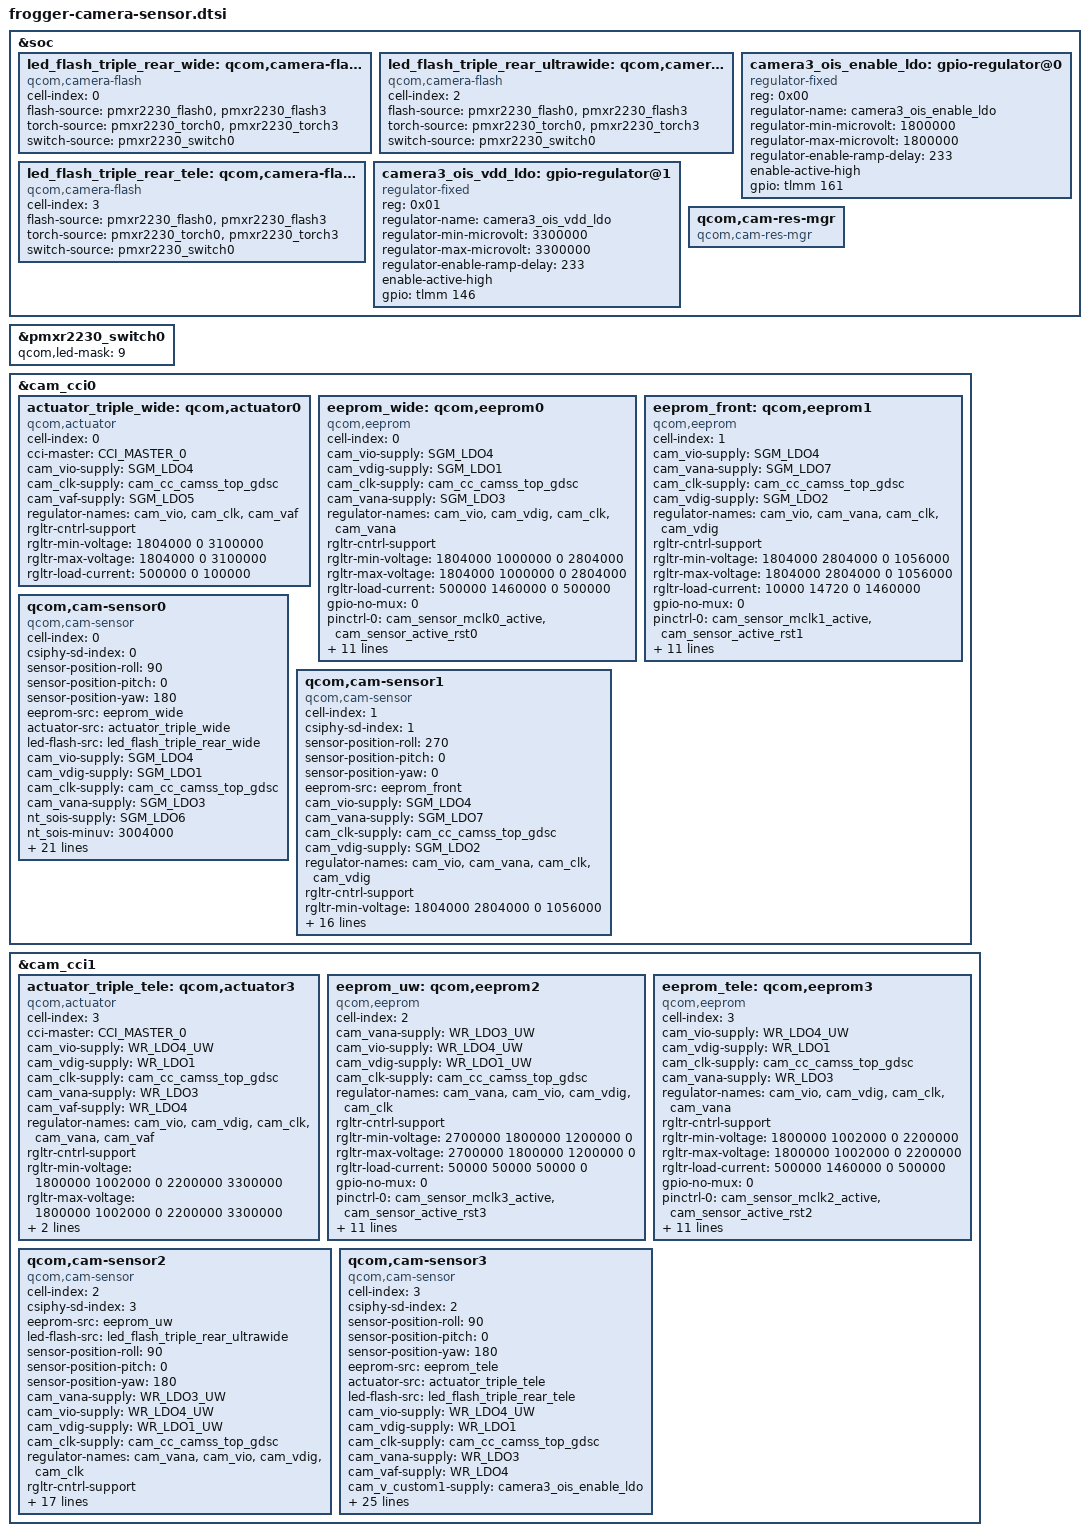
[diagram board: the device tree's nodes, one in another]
/*
 * Frogger camera sensors.
 *
 * Ported from the OEM camera-devicetree module
 * (vendor/qcom/proprietary/camera-devicetree/frogger-camera-sensor.dtsi), which
 * this tree does not carry. Kept as close to the original as possible so it can
 * be re-diffed against a newer OEM drop; only the CRLF line endings and a few
 * stray space indents were normalised.
 *
 * Four sensors:
 *   cam-sensor0  cci0  csiphy0  wide       S5KGN9,  eeprom + actuator + flash
 *   cam-sensor1  cci0  csiphy1  front      S5KKD1,  eeprom
 *   cam-sensor2  cci1  csiphy3  ultrawide  IMX355,  eeprom + flash
 *   cam-sensor3  cci1  csiphy2  tele       S5KJN5,  eeprom + actuator + OIS
 *
 * The tele is a Phone (4a) Pro part and is not populated on a plain Frogger.
 * Stock ships this same node set for both board-ids and the sensor simply fails
 * to probe when absent, so it is kept rather than stripped.
 *
 * The SGM_LDO* / WR_LDO* supplies come from frogger-camera-supply.dtsi, which
 * frogger-common.dtsi already includes into this overlay.
 *
 * cam_cci0/1, the cam_sensor_* pinctrl, camcc and the pmxr2230 flash labels are
 * NOT defined here and must not be. They come from the merged base, which is
 * volcano.dtb plus its platform dtbos, and resolve through __fixups__ at overlay
 * application -- see the comment in frogger-base-overlay.dts.
 *
 * camcc-volcano.h is needed for the CAM_CC_MCLK*_CLK clock ids. It arrives via
 * volcano.dtsi in a normal build, but this overlay includes volcano-qrd.dtsi,
 * which does not pull volcano.dtsi in, so it has to be included directly. QCOM's
 * own standalone camera .dts files do the same thing for the same reason.
 */

#include <dt-bindings/clock/qcom,camcc-volcano.h>
#include <dt-bindings/msm-camera.h>

&soc {
	led_flash_triple_rear_wide: qcom,camera-flash0 {
		cell-index = <0>;
		compatible = "qcom,camera-flash";
		flash-source = <&pmxr2230_flash0 &pmxr2230_flash3>;
		torch-source = <&pmxr2230_torch0 &pmxr2230_torch3>;
		switch-source = <&pmxr2230_switch0>;
		status = "ok";
	};

	led_flash_triple_rear_ultrawide: qcom,camera-flash1 {
		cell-index = <2>;
		compatible = "qcom,camera-flash";
		flash-source = <&pmxr2230_flash0 &pmxr2230_flash3>;
		torch-source = <&pmxr2230_torch0 &pmxr2230_torch3>;
		switch-source = <&pmxr2230_switch0>;
		status = "ok";
	};

	led_flash_triple_rear_tele: qcom,camera-flash2 {
		cell-index = <3>;
		compatible = "qcom,camera-flash";
		flash-source = <&pmxr2230_flash0 &pmxr2230_flash3>;
		torch-source = <&pmxr2230_torch0 &pmxr2230_torch3>;
		switch-source = <&pmxr2230_switch0>;
		status = "ok";
	};


	camera3_ois_enable_ldo: gpio-regulator@0 {
		compatible = "regulator-fixed";
		reg = <0x00>;
		regulator-name = "camera3_ois_enable_ldo";
		regulator-min-microvolt = <1800000>;
		regulator-max-microvolt = <1800000>;
		regulator-enable-ramp-delay = <233>;
		enable-active-high;
		gpio = <&tlmm 161 0>;
	};

	camera3_ois_vdd_ldo: gpio-regulator@1 {
		compatible = "regulator-fixed";
		reg = <0x01>;
		regulator-name = "camera3_ois_vdd_ldo";
		regulator-min-microvolt = <3300000>;
		regulator-max-microvolt = <3300000>;
		regulator-enable-ramp-delay = <233>;
		enable-active-high;
		gpio = <&tlmm 146 0>;
	};

	qcom,cam-res-mgr {
		compatible = "qcom,cam-res-mgr";
		status = "ok";
	};
};

&pmxr2230_switch0 {
	qcom,led-mask = <9>; // Channels 1 & 4
	// qcom,symmetry-en;
};

&cam_cci0 {

	actuator_triple_wide: qcom,actuator0 {
		cell-index = <0>;
		compatible = "qcom,actuator";
		cci-master = <CCI_MASTER_0>;
		cam_vio-supply = <&SGM_LDO4>;
		cam_clk-supply = <&cam_cc_camss_top_gdsc>;
		cam_vaf-supply = <&SGM_LDO5>;
		regulator-names = "cam_vio", "cam_clk", "cam_vaf";
		rgltr-cntrl-support;
		rgltr-min-voltage = <1804000 0 3100000>;
		rgltr-max-voltage = <1804000 0 3100000>;
		rgltr-load-current = <500000 0 100000>;
		status = "ok";
	};

	eeprom_wide: qcom,eeprom0 {
		cell-index = <0>;
		compatible = "qcom,eeprom";
		cam_vio-supply = <&SGM_LDO4>;
		cam_vdig-supply = <&SGM_LDO1>;
		cam_clk-supply = <&cam_cc_camss_top_gdsc>;
		cam_vana-supply = <&SGM_LDO3>;
		regulator-names = "cam_vio", "cam_vdig", "cam_clk",
			"cam_vana";
		rgltr-cntrl-support;
		rgltr-min-voltage = <1804000 1000000 0 2804000>;
		rgltr-max-voltage = <1804000 1000000 0 2804000>;
		rgltr-load-current = <500000 1460000 0 500000>;
		gpio-no-mux = <0>;
		pinctrl-names = "cam_default", "cam_suspend";
		pinctrl-0 = <&cam_sensor_mclk0_active
				 &cam_sensor_active_rst0>;
		pinctrl-1 = <&cam_sensor_mclk0_suspend
				 &cam_sensor_suspend_rst0>;
		gpios = <&tlmm 83 0>,
			<&tlmm 40 0>;
		gpio-reset = <1>;
		gpio-req-tbl-num = <0 1>;
		gpio-req-tbl-flags = <1 0>;
		gpio-req-tbl-label = "CAMIF_MCLK0",
					"CAM_RESET0";
		cci-master = <CCI_MASTER_0>;
		clocks = <&camcc CAM_CC_MCLK0_CLK>;
		clock-names = "cam_clk";
		clock-cntl-level = "nominal";
		clock-rates = <19200000>;
		status = "ok";
	};

	eeprom_front: qcom,eeprom1 {
		cell-index = <1>;
		compatible = "qcom,eeprom";
		cam_vio-supply = <&SGM_LDO4>;
		cam_vana-supply = <&SGM_LDO7>;
		cam_clk-supply = <&cam_cc_camss_top_gdsc>;
		cam_vdig-supply = <&SGM_LDO2>;
		regulator-names = "cam_vio", "cam_vana", "cam_clk", "cam_vdig";
		rgltr-cntrl-support;
		rgltr-min-voltage = <1804000 2804000 0 1056000>;
		rgltr-max-voltage = <1804000 2804000 0 1056000>;
		rgltr-load-current = <10000 14720 0 1460000>;
		gpio-no-mux = <0>;
		pinctrl-names = "cam_default", "cam_suspend";
		pinctrl-0 = <&cam_sensor_mclk1_active
				 &cam_sensor_active_rst1>;
		pinctrl-1 = <&cam_sensor_mclk1_suspend
				 &cam_sensor_suspend_rst1>;
		gpios = <&tlmm 84 0>,
			<&tlmm 41 0>;
		gpio-reset = <1>;
		gpio-req-tbl-num = <0 1>;
		gpio-req-tbl-flags = <1 0>;
		gpio-req-tbl-label = "CAMIF_MCLK1",
					"CAM_RESET1";
		cci-master = <CCI_MASTER_1>;
		clocks = <&camcc CAM_CC_MCLK1_CLK>;
		clock-names = "cam_clk";
		clock-cntl-level = "nominal";
		clock-rates = <19200000>;
		status = "ok";
	};

	/* Sensor (Wide GNJ) */
	qcom,cam-sensor0 {
		cell-index = <0>;
		compatible = "qcom,cam-sensor";
		csiphy-sd-index = <0>;
		sensor-position-roll = <90>;
		sensor-position-pitch = <0>;
		sensor-position-yaw = <180>;
		eeprom-src = <&eeprom_wide>;
		actuator-src = <&actuator_triple_wide>;
		led-flash-src = <&led_flash_triple_rear_wide>;
		cam_vio-supply = <&SGM_LDO4>;
		cam_vdig-supply = <&SGM_LDO1>;
		cam_clk-supply = <&cam_cc_camss_top_gdsc>;
		cam_vana-supply = <&SGM_LDO3>;
		// cam_v_custom1-supply = <&SGM_LDO6>;
		nt_sois-supply = <&SGM_LDO6>;
		nt_sois-minuv = <3004000>;
		nt_sois-maxuv = <3004000>;
		regulator-names = "cam_vio", "cam_vdig", "cam_clk",
			"cam_vana";
		rgltr-cntrl-support;
		rgltr-min-voltage = <1804000 1048000 0 2804000>;
		rgltr-max-voltage = <1804000 1048000 0 2804000>;
		rgltr-load-current = <500000 1460000 0 500000>;
		gpio-no-mux = <0>;
		pinctrl-names = "cam_default", "cam_suspend";
		pinctrl-0 = <&cam_sensor_mclk0_active
				 &cam_sensor_active_rst0>;
		pinctrl-1 = <&cam_sensor_mclk0_suspend
				 &cam_sensor_suspend_rst0>;
		gpios = <&tlmm 83 0>,
			<&tlmm 40 0>;
		gpio-reset = <1>;
		gpio-req-tbl-num = <0 1>;
		gpio-req-tbl-flags = <1 0>;
		gpio-req-tbl-label = "CAMIF_MCLK0",
					"CAM_RESET0";
		cci-master = <CCI_MASTER_0>;
		clocks = <&camcc CAM_CC_MCLK0_CLK>;
		clock-names = "cam_clk";
		clock-cntl-level = "nominal";
		clock-rates = <19200000>;
		status = "ok";
	};

	/*sensor front 32M*/
	qcom,cam-sensor1 {
		cell-index = <1>;
		compatible = "qcom,cam-sensor";
		csiphy-sd-index = <1>;
		sensor-position-roll = <270>;
		sensor-position-pitch = <0>;
		sensor-position-yaw = <0>;
		eeprom-src = <&eeprom_front>;
		cam_vio-supply = <&SGM_LDO4>;
		cam_vana-supply = <&SGM_LDO7>;
		cam_clk-supply = <&cam_cc_camss_top_gdsc>;
		cam_vdig-supply = <&SGM_LDO2>;
		regulator-names = "cam_vio", "cam_vana", "cam_clk", "cam_vdig";
		rgltr-cntrl-support;
		rgltr-min-voltage = <1804000 2804000 0 1056000>;
		rgltr-max-voltage = <1804000 2804000 0 1056000>;
		rgltr-load-current = <10000 14720 0 1460000>;
		gpio-no-mux = <0>;
		pinctrl-names = "cam_default", "cam_suspend";
		pinctrl-0 = <&cam_sensor_mclk1_active
				 &cam_sensor_active_rst1>;
		pinctrl-1 = <&cam_sensor_mclk1_suspend
				 &cam_sensor_suspend_rst1>;
		gpios = <&tlmm 84 0>,
			<&tlmm 41 0>;
		gpio-reset = <1>;
		gpio-req-tbl-num = <0 1>;
		gpio-req-tbl-flags = <1 0>;
		gpio-req-tbl-label = "CAMIF_MCLK1",
					"CAM_RESET1";
		cci-master = <CCI_MASTER_1>;
		clocks = <&camcc CAM_CC_MCLK1_CLK>;
		clock-names = "cam_clk";
		clock-cntl-level = "nominal";
		clock-rates = <19200000>;
		status = "ok";
	};
};

&cam_cci1 {
		actuator_triple_tele: qcom,actuator3 {
		cell-index = <3>;
		compatible = "qcom,actuator";
		cci-master = <CCI_MASTER_0>;
		cam_vio-supply = <&WR_LDO4_UW>;
		cam_vdig-supply = <&WR_LDO1>;
		cam_clk-supply = <&cam_cc_camss_top_gdsc>;
		cam_vana-supply = <&WR_LDO3>;
		cam_vaf-supply = <&WR_LDO4>;
		regulator-names = "cam_vio", "cam_vdig", "cam_clk", "cam_vana", "cam_vaf";
		rgltr-cntrl-support;
		rgltr-min-voltage = <1800000 1002000 0 2200000 3300000>;
		rgltr-max-voltage = <1800000 1002000 0 2200000 3300000>;
		rgltr-load-current = <500000 1460000 0 500000 100000>;
		status = "ok";
	};

	eeprom_uw: qcom,eeprom2 {
		cell-index = <2>;
		compatible = "qcom,eeprom";
		cam_vana-supply = <&WR_LDO3_UW>;
		cam_vio-supply = <&WR_LDO4_UW>;
		cam_vdig-supply = <&WR_LDO1_UW>;
		cam_clk-supply = <&cam_cc_camss_top_gdsc>;
		regulator-names = "cam_vana", "cam_vio", "cam_vdig",
			 "cam_clk";
		rgltr-cntrl-support;
		rgltr-min-voltage = <2700000 1800000 1200000 0>;
		rgltr-max-voltage = <2700000 1800000 1200000 0>;
		rgltr-load-current = <50000 50000 50000 0>;
		gpio-no-mux = <0>;
		pinctrl-names = "cam_default", "cam_suspend";
		pinctrl-0 = <&cam_sensor_mclk3_active
			&cam_sensor_active_rst3>;
		pinctrl-1 = <&cam_sensor_mclk3_suspend
			&cam_sensor_suspend_rst3>;
		gpios = <&tlmm 86 0>, <&tlmm 43 0>;
		gpio-reset = <1>;
		gpio-req-tbl-num = <0 1>;
		gpio-req-tbl-flags = <1 0>;
		gpio-req-tbl-label = "CAMIF_MCLK3", "CAM_RESET3";
		cci-master = <CCI_MASTER_1>;
		clocks = <&camcc CAM_CC_MCLK3_CLK>;
		clock-names = "cam_clk";
		clock-cntl-level = "nominal";
		clock-rates = <19200000>;
		status = "ok";
	};

	eeprom_tele: qcom,eeprom3{
		cell-index = <3>;
		compatible = "qcom,eeprom";
		cam_vio-supply = <&WR_LDO4_UW>;
		cam_vdig-supply = <&WR_LDO1>;
		cam_clk-supply = <&cam_cc_camss_top_gdsc>;
		cam_vana-supply = <&WR_LDO3>;
		regulator-names = "cam_vio", "cam_vdig", "cam_clk", "cam_vana";
		rgltr-cntrl-support;
		rgltr-min-voltage = <1800000 1002000 0 2200000>;
		rgltr-max-voltage = <1800000 1002000 0 2200000>;
		rgltr-load-current = <500000 1460000 0 500000>;
		gpio-no-mux = <0>;
		pinctrl-names = "cam_default", "cam_suspend";
		pinctrl-0 = <&cam_sensor_mclk2_active
				 &cam_sensor_active_rst2>;
		pinctrl-1 = <&cam_sensor_mclk2_suspend
				 &cam_sensor_suspend_rst2>;
		gpios = <&tlmm 85 0>,
			<&tlmm 42 0>;
		gpio-reset = <1>;
		gpio-req-tbl-num = <0 1>;
		gpio-req-tbl-flags = <1 0>;
		gpio-req-tbl-label = "CAMIF_MCLK2",
					"CAM_RESET2";
		cci-master = <CCI_MASTER_0>;
		clocks = <&camcc CAM_CC_MCLK2_CLK>;
		clock-names = "cam_clk";
		clock-cntl-level = "nominal";
		clock-rates = <19200000>;
		status = "ok";
	};

	/* Sensor (Ultra imx355) */
	qcom,cam-sensor2 {
		cell-index = <2>;
		compatible = "qcom,cam-sensor";
		csiphy-sd-index = <3>;
		eeprom-src = <&eeprom_uw>;
		led-flash-src = <&led_flash_triple_rear_ultrawide>;
		sensor-position-roll = <90>;
		sensor-position-pitch = <0>;
		sensor-position-yaw = <180>;
		cam_vana-supply = <&WR_LDO3_UW>;
		cam_vio-supply = <&WR_LDO4_UW>;
		cam_vdig-supply = <&WR_LDO1_UW>;
		cam_clk-supply = <&cam_cc_camss_top_gdsc>;
		regulator-names = "cam_vana", "cam_vio", "cam_vdig",
			 "cam_clk";
		rgltr-cntrl-support;
		rgltr-min-voltage = <2700000 1800000 1200000 0>;
		rgltr-max-voltage = <2700000 1800000 1200000 0>;
		rgltr-load-current = <50000 50000 50000 0>;
		gpio-no-mux = <0>;
		pinctrl-names = "cam_default", "cam_suspend";
		pinctrl-0 = <&cam_sensor_mclk3_active
			&cam_sensor_active_rst3>;
		pinctrl-1 = <&cam_sensor_mclk3_suspend
			&cam_sensor_suspend_rst3>;
		gpios = <&tlmm 86 0>, <&tlmm 43 0>;
		gpio-reset = <1>;
		gpio-req-tbl-num = <0 1>;
		gpio-req-tbl-flags = <1 0>;
		gpio-req-tbl-label = "CAMIF_MCLK3", "CAM_RESET3";
		cci-master = <CCI_MASTER_1>;
		clocks = <&camcc CAM_CC_MCLK3_CLK>;
		clock-names = "cam_clk";
		clock-cntl-level = "nominal";
		clock-rates = <19200000>;
		status = "ok";
	};

	/* Sensor (Tele GN5 3M5) */
	qcom,cam-sensor3 {
		cell-index = <3>;
		compatible = "qcom,cam-sensor";
		csiphy-sd-index = <2>;
		sensor-position-roll = <90>;
		sensor-position-pitch = <0>;
		sensor-position-yaw = <180>;
		eeprom-src = <&eeprom_tele>;
		actuator-src = <&actuator_triple_tele>;
		led-flash-src = <&led_flash_triple_rear_tele>;
		cam_vio-supply = <&WR_LDO4_UW>;
		cam_vdig-supply = <&WR_LDO1>;
		cam_clk-supply = <&cam_cc_camss_top_gdsc>;
		cam_vana-supply = <&WR_LDO3>;
		cam_vaf-supply = <&WR_LDO4>;
		cam_v_custom1-supply = <&camera3_ois_enable_ldo>;
		cam_v_custom2-supply = <&camera3_ois_vdd_ldo>;
		regulator-names = "cam_vio", "cam_vdig", "cam_clk", "cam_vana", "cam_vaf",
				"cam_v_custom1","cam_v_custom2";
		rgltr-cntrl-support;
		rgltr-min-voltage = <1800000 1002000 0 2200000 3300000 1800000 3300000>;
		rgltr-max-voltage = <1800000 1002000 0 2200000 3300000 1800000 3300000>;
		rgltr-load-current = <500000 1460000 0 500000 50000 1050000 1800000>;
		gpio-no-mux = <0>;
		pinctrl-names = "cam_default", "cam_suspend";
		pinctrl-0 = <&cam_sensor_mclk2_active
				 &cam_sensor_active_rst2>;
		pinctrl-1 = <&cam_sensor_mclk2_suspend
				 &cam_sensor_suspend_rst2>;
		gpios = <&tlmm 85 0>,
			<&tlmm 42 0>;
		gpio-reset = <1>;
		gpio-req-tbl-num = <0 1>;
		gpio-req-tbl-flags = <1 0>;
		gpio-req-tbl-label = "CAMIF_MCLK2",
					"CAM_RESET2";
		cci-master = <CCI_MASTER_0>;
		clocks = <&camcc CAM_CC_MCLK2_CLK>;
		clock-names = "cam_clk";
		clock-cntl-level = "nominal";
		clock-rates = <19200000>;
		status = "ok";
	};
};
